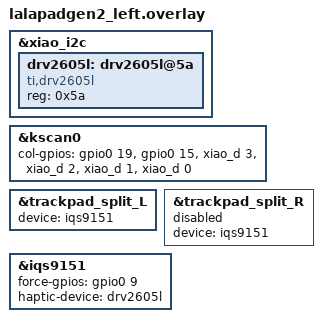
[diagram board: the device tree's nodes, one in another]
#include "lalapadgen2.dtsi"

&xiao_i2c {
    drv2605l: drv2605l@5a {
        compatible = "ti,drv2605l";
        reg = <0x5a>;
        status = "okay";
    };
};

&kscan0 {
    col-gpios
        = <&gpio0 19 GPIO_ACTIVE_HIGH>
        , <&gpio0 15 GPIO_ACTIVE_HIGH>
        , <&xiao_d 3 GPIO_ACTIVE_HIGH>
        , <&xiao_d 2 GPIO_ACTIVE_HIGH>
        , <&xiao_d 1 GPIO_ACTIVE_HIGH>
        , <&xiao_d 0 GPIO_ACTIVE_HIGH>
        ;
};

&trackpad_split_L {
    status = "okay";
    device = <&iqs9151>;
};
&trackpad_split_R {
    status = "disabled";
    device = <&iqs9151>;
};

&iqs9151 {
    /* D14 / P0.09 is used as a digital threshold input for the FSR divider. */
    force-gpios = <&gpio0 9 GPIO_ACTIVE_HIGH>;
    haptic-device = <&drv2605l>;
};
